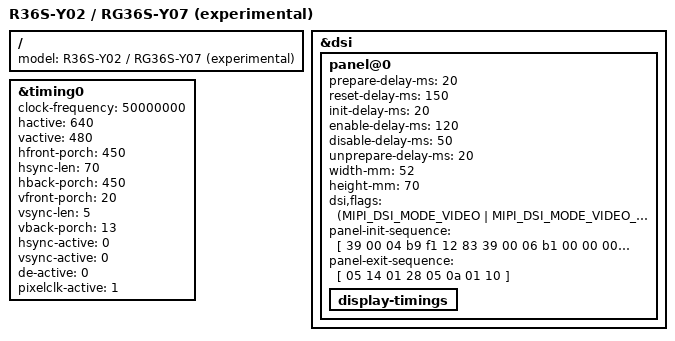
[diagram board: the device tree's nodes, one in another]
// SPDX-License-Identifier: (GPL-2.0+ OR MIT)
/*
 * EXPERIMENTAL - not tested on hardware by andr36oid. Keep a copy of the
 * files you replace so you can go back.
 *
 * R36S-Y02 (2024-11-27, 2024-12-18) and RG36S-Y07 (2025-09-11): genuine
 * R36S wiring with the EE clone "Panel 8" run at 50 MHz.
 * Source: dArkOSRE ports by southoz (dArkOSRE-R36, r36s/R36S-Y02, RG36S-Y07).
 */

/dts-v1/;
#include "rk3326-r36s-android.dtsi"

/ {
	model = "R36S-Y02 / RG36S-Y07 (experimental)";
};

&dsi {
	panel@0 {
		prepare-delay-ms = <20>;
		reset-delay-ms = <150>;
		init-delay-ms = <20>;
		enable-delay-ms = <120>;
		disable-delay-ms = <50>;
		unprepare-delay-ms = <20>;
		width-mm = <52>;
		height-mm = <70>;
		dsi,flags = <(MIPI_DSI_MODE_VIDEO |
		      MIPI_DSI_MODE_VIDEO_BURST |
		      MIPI_DSI_MODE_EOT_PACKET |
		      MIPI_DSI_MODE_LPM)>;
		panel-init-sequence = [
			39 00 04 b9 f1 12 83
			39 00 06 b1 00 00 00 da 80
			39 00 04 b2 00 13 70
			39 00 0b b3 10 10 28 28 03 ff 00 00 00 00
			15 00 02 b4 80
			15 00 03 b5 0a 0a
			15 00 03 b6 82 82
			39 00 05 b8 26 62 f0 63
			39 00 1c ba 33 81 05 f9 0e 0e 20 00 00 00 00 00 00 00 44 25 00 90 0a 00 00 01 4f 01 00 00 37
			15 00 02 bc 47
			39 00 04 bf 02 11 00
			39 00 0a c0 73 73 50 50 00 00 12 50 00
			39 00 0d c1 53 00 32 32 77 d1 cc cc 77 77 33 33
			39 00 07 c6 82 00 bf ff 00 ff
			39 00 07 c7 b8 00 0a 00 00 00
			39 00 05 c8 10 40 1e 02
			15 00 02 cc 0b
			39 00 23 e0 00 07 0d 37 35 3f 41 44 06 0c 0d 0f 11 10 12 14 1a 00 07 0d 37 35 3f 41 44 06 0c 0d 0f 11 10 12 14 1a
			39 00 0f e3 07 07 0b 0b 0b 0b 00 00 00 00 ff 00 c0 10
			39 00 40 e9 c8 10 02 00 00 b0 b1 11 31 23 28 80 b0 b1 27 08 00 04 02 00 00 00 00 04 02 00 00 00 88 88 ba 60 24 08 88 88 88 88 88 88 88 ba 71 35 18 88 88 88 88 88 00 00 00 01 00 00 00 00 00 00 00 00 00
			39 00 3e ea 97 0a 82 02 03 07 00 00 00 00 00 00 81 88 ba 17 53 88 88 88 88 88 88 80 88 ba 06 42 88 88 88 88 88 88 23 00 00 02 80 00 00 00 00 00 00 00 00 00 00 00 00 00 00 00 00 00 00 00 00 00 00
			39 00 04 ef ff ff 01
			05 c8 01 11
			05 14 01 29
		];
		panel-exit-sequence = [
			05 14 01 28
			05 0a 01 10
		];
		display-timings {
			/* one mode only: the R36S alternates below do not fit this panel */
			/delete-node/ timing1;
			/delete-node/ timing2;
		};
	};
};

&timing0 {
	clock-frequency = <50000000>;
	hactive = <640>;
	vactive = <480>;
	hfront-porch = <450>;
	hsync-len = <70>;
	hback-porch = <450>;
	vfront-porch = <20>;	/* was 17: 60.3 Hz; 59.95 Hz, same pixel clock */
	vsync-len = <5>;
	vback-porch = <13>;
	hsync-active = <0>;
	vsync-active = <0>;
	de-active = <0>;
	pixelclk-active = <1>;
};
